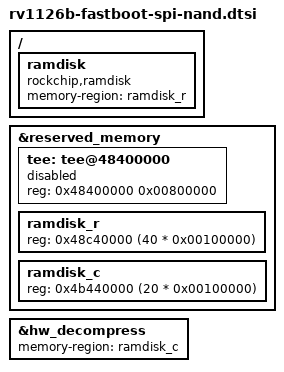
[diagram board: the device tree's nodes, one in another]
// SPDX-License-Identifier: (GPL-2.0+ OR MIT)
/*
 * Copyright (c) 2025 Rockchip Electronics Co., Ltd.
 */

/ {
	ramdisk: ramdisk {
		compatible = "rockchip,ramdisk";
		memory-region = <&ramdisk_r>;
	};
};

&reserved_memory {
	/* Should enable this node if the security feature is enabled, like TA. */
	tee: tee@48400000 {
		reg = <0x48400000 0x00800000>;
		status = "disabled";
	};

	ramdisk_r: ramdisk_r {
		reg = <0x48c40000 (40 * 0x00100000)>;
	};

	ramdisk_c: ramdisk_c {
		reg = <0x4b440000 (20 * 0x00100000)>;
	};
};

&hw_decompress {
	memory-region = <&ramdisk_c>;
	status = "okay";
};
